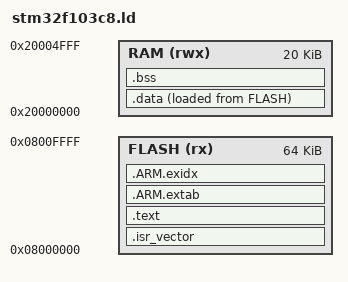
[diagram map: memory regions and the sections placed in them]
/* STM32F103C8: use the documented 64KiB flash, not unofficial larger capacity. */
ENTRY(Reset_Handler)
MEMORY
{
  FLASH (rx)  : ORIGIN = 0x08000000, LENGTH = 64K
  RAM   (rwx) : ORIGIN = 0x20000000, LENGTH = 20K
}
_estack = ORIGIN(RAM) + LENGTH(RAM);
_Min_Stack_Size = 0x1000;
SECTIONS
{
  .isr_vector : { . = ALIGN(4); KEEP(*(.isr_vector)) . = ALIGN(4); } > FLASH
  .text :
  {
    . = ALIGN(4); *(.text*) *(.rodata*)
    KEEP(*(.init)) KEEP(*(.fini))
    . = ALIGN(4);
  } > FLASH
  .ARM.extab : { *(.ARM.extab* .gnu.linkonce.armextab.*) } > FLASH
  .ARM.exidx :
  { __exidx_start = .; *(.ARM.exidx*) __exidx_end = .; } > FLASH
  .data :
  {
    . = ALIGN(4); _sdata = .; *(.data*) . = ALIGN(4); _edata = .;
  } > RAM AT> FLASH
  _sidata = LOADADDR(.data);
  .bss (NOLOAD) :
  {
    . = ALIGN(4); _sbss = .; *(.bss*) *(COMMON) . = ALIGN(4); _ebss = .;
  } > RAM
  _end = .;
  end = .;
  ASSERT(_ebss <= _estack - _Min_Stack_Size, "RAM overflow: less than 4KiB stack remains")
  /DISCARD/ : { *(.note.GNU-stack) }
}
